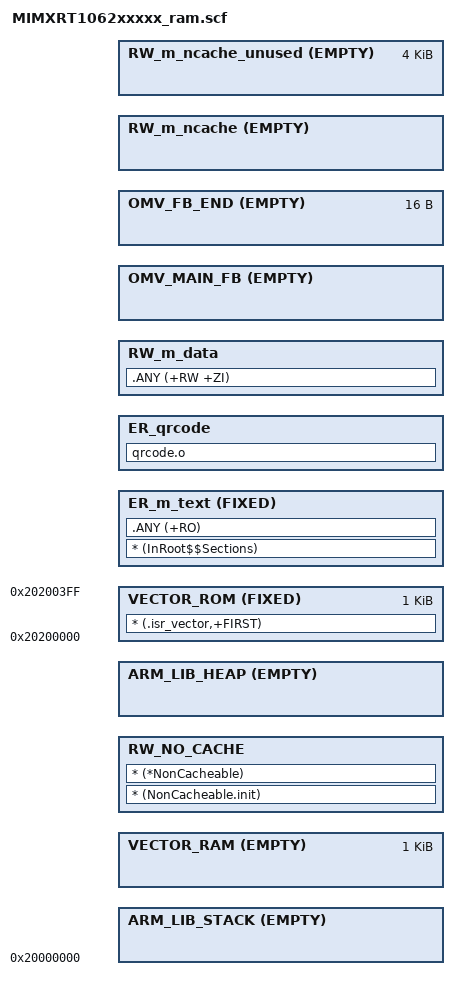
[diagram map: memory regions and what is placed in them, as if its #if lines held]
#!armclang --target=arm-arm-none-eabi -mcpu=cortex-m7 -E -x c
/*
** ###################################################################
**     Processors:          MIMXRT1062CVJ5A
**                          MIMXRT1062CVL5A
**                          MIMXRT1062DVJ6A
**                          MIMXRT1062DVL6A
**
**     Compiler:            Keil ARM C/C++ Compiler
**     Reference manual:    IMXRT1060RM Rev.1, 12/2018 | IMXRT1060SRM Rev.3
**     Version:             rev. 0.1, 2017-01-10
**     Build:               b191015
**
**     Abstract:
**         Linker file for the Keil ARM C/C++ Compiler
**
**     Copyright 2016 Freescale Semiconductor, Inc.
**     Copyright 2016-2019 NXP
**     All rights reserved.
**
**     SPDX-License-Identifier: BSD-3-Clause
**
**     http:                 www.nxp.com
**     mail:                 support@nxp.com
**
** ###################################################################
*/

#define dtcm_start             0x20000000
#define dtcm_size              0x00008000

#define ocram_start            0x20200000
#define ocram_size             0x000F8000

#include "../omv/omv_lib/examples_port.h"
	
/* Sizes */
#if (defined(__stack_size__))
  #define Stack_Size                   __stack_size__
#else
  #define Stack_Size                   0x1000
#endif

#if (defined(__heap_size__))
  #define Heap_Size                    __heap_size__
#else
  #define Heap_Size                    0x2000
#endif
	
#define m_interrupts_size                  0x400 
#define m_ncache_unused_size               0x1000

LR_m_text ocram_start ocram_size {   ; load region size_region
  VECTOR_ROM ocram_start FIXED m_interrupts_size { ; load address = execution address
    * (.isr_vector,+FIRST)
  }
  ER_m_text +0 FIXED  { ; load address = execution address
    * (InRoot$$Sections)
    .ANY (+RO)
  }
  ER_qrcode +0  {
	qrcode.o
  }
  RW_m_data +0 { ; RW data
    .ANY (+RW +ZI)
  }
  ; >>>
  OMV_MAIN_FB +0 EMPTY OMV_MAIN_FB_SIZE+OMV_FB_ALLOC_SIZE {}
  OMV_FB_END +0 EMPTY 16 {}	
  ; >>>
  
  RW_m_ncache +0 EMPTY 0 {
  }
  RW_m_ncache_unused +0 EMPTY m_ncache_unused_size { ; Empty region added for MPU configuration
  }
  
  ; 32K dtcm for STACK + VECTOR + HEAP
  ARM_LIB_STACK dtcm_start EMPTY Stack_Size {    ; Heap region growing up
  }
  
  VECTOR_RAM +0 EMPTY m_interrupts_size {
  }
  
  RW_NO_CACHE +0 {
    * (NonCacheable.init)
    * (*NonCacheable)
  }
  ARM_LIB_HEAP dtcm_start+dtcm_size EMPTY -Heap_Size { ; Stack region growing down
  }
}
